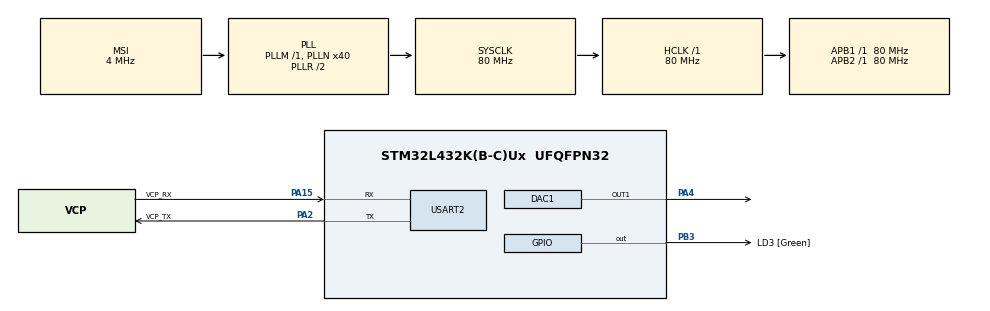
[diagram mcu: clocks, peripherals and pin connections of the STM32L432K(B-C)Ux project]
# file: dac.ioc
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DAC1.DAC_Trigger-DAC_OUT1=DAC_TRIGGER_T6_TRGO
Dma.DAC_CH1.0.Direction=DMA_MEMORY_TO_PERIPH
Dma.DAC_CH1.0.Instance=DMA1_Channel3
Dma.DAC_CH1.0.MemDataAlignment=DMA_MDATAALIGN_BYTE
Dma.DAC_CH1.0.MemInc=DMA_MINC_ENABLE
Dma.DAC_CH1.0.Mode=DMA_NORMAL
Dma.DAC_CH1.0.PeriphDataAlignment=DMA_PDATAALIGN_BYTE
Dma.DAC_CH1.0.PeriphInc=DMA_PINC_DISABLE
Dma.DAC_CH1.0.Priority=DMA_PRIORITY_LOW
Dma.Request0=DAC_CH1
Mcu.Family=STM32L4
Mcu.Name=STM32L432K(B-C)Ux
Mcu.Package=UFQFPN32
NVIC.DMA1_Channel3_IRQn=true\:0\:0\:false\:false\:true\:false
NVIC.PriorityGroup=NVIC_PRIORITYGROUP_4
PA0.GPIO_Label=MCO [High speed clock in]
PA0.Mode=HSE-External-Clock-Source-for-LittleOrca
PA0.Signal=RCC_CK_IN
PA13\ (JTMS-SWDIO).GPIO_Label=SWDIO
PA13\ (JTMS-SWDIO).Mode=Serial_Wire
PA13\ (JTMS-SWDIO).Signal=SYS_JTMS-SWDIO
PA14\ (JTCK-SWCLK).GPIO_Label=SWCLK
PA14\ (JTCK-SWCLK).Mode=Serial_Wire
PA14\ (JTCK-SWCLK).Signal=SYS_JTCK-SWCLK
PA15\ (JTDI).GPIO_Label=VCP_RX
PA15\ (JTDI).Mode=Asynchronous
PA15\ (JTDI).Signal=USART2_RX
PA2.GPIO_Label=VCP_TX
PA2.Mode=Asynchronous
PA2.Signal=USART2_TX
PA4.Signal=COMP_DAC11_group
PB3\ (JTDO-TRACESWO).GPIO_Label=LD3 [Green]
PB3\ (JTDO-TRACESWO).Signal=GPIO_Output
PC14-OSC32_IN\ (PC14).Mode=LSE-External-Oscillator
PC14-OSC32_IN\ (PC14).Signal=RCC_OSC32_IN
PC15-OSC32_OUT\ (PC15).Mode=LSE-External-Oscillator
PC15-OSC32_OUT\ (PC15).Signal=RCC_OSC32_OUT
ProjectManager.HeapSize=0x200
ProjectManager.StackSize=0x400
ProjectManager.TargetToolchain=TrueSTUDIO
RCC.AHBFreq_Value=80000000
RCC.APB1Freq_Value=80000000
RCC.APB1TimFreq_Value=80000000
RCC.APB2Freq_Value=80000000
RCC.APB2TimFreq_Value=80000000
RCC.CortexFreq_Value=80000000
RCC.HCLKFreq_Value=80000000
RCC.HSE_VALUE=8000000
RCC.HSI16_VALUE=16000000
RCC.HSI48_VALUE=48000000
RCC.HSI_VALUE=16000000
RCC.MSI_VALUE=4000000
RCC.PLLMUL=RCC_PLLMUL_4
RCC.PLLN=40
RCC.SYSCLKFreq_VALUE=80000000
RCC.SYSCLKSource=RCC_SYSCLKSOURCE_PLLCLK
RCC.VCOOutputFreq_Value=160000000
SH.COMP_DAC11_group.0=DAC1_OUT1,DAC_OUT1
TIM6.Period=1000
TIM6.Prescaler=10
TIM6.TIM_MasterOutputTrigger=TIM_TRGO_UPDATE
USART2.VirtualMode-Asynchronous=VM_ASYNC
VP_TIM6_VS_ClockSourceINT.Mode=Enable_Timer
board=NUCLEO-L432KC

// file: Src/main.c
/**
  ******************************************************************************
  * @file           : main.c
  * @brief          : Main program body
  ******************************************************************************
  ** This notice applies to any and all portions of this file
  * that are not between comment pairs USER CODE BEGIN and
  * USER CODE END. Other portions of this file, whether
  * inserted by the user or by software development tools
  * are owned by their respective copyright owners.
  *
  * COPYRIGHT(c) 2018 STMicroelectronics
  *
  * Redistribution and use in source and binary forms, with or without modification,
  * are permitted provided that the following conditions are met:
  *   1. Redistributions of source code must retain the above copyright notice,
  *      this list of conditions and the following disclaimer.
  *   2. Redistributions in binary form must reproduce the above copyright notice,
  *      this list of conditions and the following disclaimer in the documentation
  *      and/or other materials provided with the distribution.
  *   3. Neither the name of STMicroelectronics nor the names of its contributors
  *      may be used to endorse or promote products derived from this software
  *      without specific prior written permission.
  *
  * THIS SOFTWARE IS PROVIDED BY THE COPYRIGHT HOLDERS AND CONTRIBUTORS "AS IS"
  * AND ANY EXPRESS OR IMPLIED WARRANTIES, INCLUDING, BUT NOT LIMITED TO, THE
  * IMPLIED WARRANTIES OF MERCHANTABILITY AND FITNESS FOR A PARTICULAR PURPOSE ARE
  * DISCLAIMED. IN NO EVENT SHALL THE COPYRIGHT HOLDER OR CONTRIBUTORS BE LIABLE
  * FOR ANY DIRECT, INDIRECT, INCIDENTAL, SPECIAL, EXEMPLARY, OR CONSEQUENTIAL
  * DAMAGES (INCLUDING, BUT NOT LIMITED TO, PROCUREMENT OF SUBSTITUTE GOODS OR
  * SERVICES; LOSS OF USE, DATA, OR PROFITS; OR BUSINESS INTERRUPTION) HOWEVER
  * CAUSED AND ON ANY THEORY OF LIABILITY, WHETHER IN CONTRACT, STRICT LIABILITY,
  * OR TORT (INCLUDING NEGLIGENCE OR OTHERWISE) ARISING IN ANY WAY OUT OF THE USE
  * OF THIS SOFTWARE, EVEN IF ADVISED OF THE POSSIBILITY OF SUCH DAMAGE.
  *
  ******************************************************************************
  */
#include "main.h"
#include "stm32l4xx_hal.h"

/* USER CODE BEGIN Includes */

#include "sampleplayer.h"

/* USER CODE END Includes */

DAC_HandleTypeDef hdac1;
DMA_HandleTypeDef hdma_dac_ch1;

TIM_HandleTypeDef htim6;

UART_HandleTypeDef huart2;

/* USER CODE BEGIN PV */
/* Private variables ---------------------------------------------------------*/

/* USER CODE END PV */

void SystemClock_Config(void);
static void MX_GPIO_Init(void);
static void MX_DMA_Init(void);
static void MX_USART2_UART_Init(void);
static void MX_DAC1_Init(void);
static void MX_TIM6_Init(void);

/* USER CODE BEGIN PFP */
/* Private function prototypes -----------------------------------------------*/

/* USER CODE END PFP */

int main(void)
{

  /* MCU Configuration----------------------------------------------------------*/

  /* Reset of all peripherals, Initializes the Flash interface and the Systick. */
  HAL_Init();

  /* Configure the system clock */
  SystemClock_Config();

  /* Initialize all configured peripherals */
  MX_GPIO_Init();
  MX_DMA_Init();
  MX_USART2_UART_Init();
  MX_DAC1_Init();
  MX_TIM6_Init();
  /* USER CODE BEGIN 2 */

  sampleplayer_init();

  /* USER CODE END 2 */

  /* Infinite loop */
  while (1)
  {

  /* USER CODE BEGIN 3 */

    sampleplayer_play_click();
    HAL_Delay(500);

  }
  /* USER CODE END 3 */

}

void SystemClock_Config(void)
{

  RCC_OscInitTypeDef RCC_OscInitStruct;
  RCC_ClkInitTypeDef RCC_ClkInitStruct;
  RCC_PeriphCLKInitTypeDef PeriphClkInit;

    /**Configure LSE Drive Capability
    */
  __HAL_RCC_LSEDRIVE_CONFIG(RCC_LSEDRIVE_LOW);

    /**Initializes the CPU, AHB and APB busses clocks
    */
  RCC_OscInitStruct.OscillatorType = RCC_OSCILLATORTYPE_LSE|RCC_OSCILLATORTYPE_MSI;
  RCC_OscInitStruct.LSEState = RCC_LSE_ON;
  RCC_OscInitStruct.MSIState = RCC_MSI_ON;
  RCC_OscInitStruct.MSICalibrationValue = 0;
  RCC_OscInitStruct.MSIClockRange = RCC_MSIRANGE_6;
  RCC_OscInitStruct.PLL.PLLState = RCC_PLL_ON;
  RCC_OscInitStruct.PLL.PLLSource = RCC_PLLSOURCE_MSI;
  RCC_OscInitStruct.PLL.PLLM = 1;
  RCC_OscInitStruct.PLL.PLLN = 40;
  RCC_OscInitStruct.PLL.PLLP = RCC_PLLP_DIV7;
  RCC_OscInitStruct.PLL.PLLQ = RCC_PLLQ_DIV2;
  RCC_OscInitStruct.PLL.PLLR = RCC_PLLR_DIV2;
  if (HAL_RCC_OscConfig(&RCC_OscInitStruct) != HAL_OK)
  {
    _Error_Handler(__FILE__, __LINE__);
  }

    /**Initializes the CPU, AHB and APB busses clocks
    */
  RCC_ClkInitStruct.ClockType = RCC_CLOCKTYPE_HCLK|RCC_CLOCKTYPE_SYSCLK
                              |RCC_CLOCKTYPE_PCLK1|RCC_CLOCKTYPE_PCLK2;
  RCC_ClkInitStruct.SYSCLKSource = RCC_SYSCLKSOURCE_PLLCLK;
  RCC_ClkInitStruct.AHBCLKDivider = RCC_SYSCLK_DIV1;
  RCC_ClkInitStruct.APB1CLKDivider = RCC_HCLK_DIV1;
  RCC_ClkInitStruct.APB2CLKDivider = RCC_HCLK_DIV1;

  if (HAL_RCC_ClockConfig(&RCC_ClkInitStruct, FLASH_LATENCY_4) != HAL_OK)
  {
    _Error_Handler(__FILE__, __LINE__);
  }

  PeriphClkInit.PeriphClockSelection = RCC_PERIPHCLK_USART2;
  PeriphClkInit.Usart2ClockSelection = RCC_USART2CLKSOURCE_PCLK1;
  if (HAL_RCCEx_PeriphCLKConfig(&PeriphClkInit) != HAL_OK)
  {
    _Error_Handler(__FILE__, __LINE__);
  }

    /**Configure the main internal regulator output voltage
    */
  if (HAL_PWREx_ControlVoltageScaling(PWR_REGULATOR_VOLTAGE_SCALE1) != HAL_OK)
  {
    _Error_Handler(__FILE__, __LINE__);
  }

    /**Configure the Systick interrupt time
    */
  HAL_SYSTICK_Config(HAL_RCC_GetHCLKFreq()/1000);

    /**Configure the Systick
    */
  HAL_SYSTICK_CLKSourceConfig(SYSTICK_CLKSOURCE_HCLK);

    /**Enable MSI Auto calibration
    */
  HAL_RCCEx_EnableMSIPLLMode();

  /* SysTick_IRQn interrupt configuration */
  HAL_NVIC_SetPriority(SysTick_IRQn, 0, 0);
}

/* DAC1 init function */
static void MX_DAC1_Init(void)
{

  DAC_ChannelConfTypeDef sConfig;

    /**DAC Initialization
    */
  hdac1.Instance = DAC1;
  if (HAL_DAC_Init(&hdac1) != HAL_OK)
  {
    _Error_Handler(__FILE__, __LINE__);
  }

    /**DAC channel OUT1 config
    */
  sConfig.DAC_SampleAndHold = DAC_SAMPLEANDHOLD_DISABLE;
  sConfig.DAC_Trigger = DAC_TRIGGER_T6_TRGO;
  sConfig.DAC_OutputBuffer = DAC_OUTPUTBUFFER_ENABLE;
  sConfig.DAC_ConnectOnChipPeripheral = DAC_CHIPCONNECT_DISABLE;
  sConfig.DAC_UserTrimming = DAC_TRIMMING_FACTORY;
  if (HAL_DAC_ConfigChannel(&hdac1, &sConfig, DAC_CHANNEL_1) != HAL_OK)
  {
    _Error_Handler(__FILE__, __LINE__);
  }

}

/* TIM6 init function */
static void MX_TIM6_Init(void)
{

  TIM_MasterConfigTypeDef sMasterConfig;

  htim6.Instance = TIM6;
  htim6.Init.Prescaler = 10;
  htim6.Init.CounterMode = TIM_COUNTERMODE_UP;
  htim6.Init.Period = 1000;
  htim6.Init.AutoReloadPreload = TIM_AUTORELOAD_PRELOAD_DISABLE;
  if (HAL_TIM_Base_Init(&htim6) != HAL_OK)
  {
    _Error_Handler(__FILE__, __LINE__);
  }

  sMasterConfig.MasterOutputTrigger = TIM_TRGO_UPDATE;
  sMasterConfig.MasterSlaveMode = TIM_MASTERSLAVEMODE_DISABLE;
  if (HAL_TIMEx_MasterConfigSynchronization(&htim6, &sMasterConfig) != HAL_OK)
  {
    _Error_Handler(__FILE__, __LINE__);
  }

}

/* USART2 init function */
static void MX_USART2_UART_Init(void)
{

  huart2.Instance = USART2;
  huart2.Init.BaudRate = 115200;
  huart2.Init.WordLength = UART_WORDLENGTH_7B;
  huart2.Init.StopBits = UART_STOPBITS_1;
  huart2.Init.Parity = UART_PARITY_NONE;
  huart2.Init.Mode = UART_MODE_TX_RX;
  huart2.Init.HwFlowCtl = UART_HWCONTROL_NONE;
  huart2.Init.OverSampling = UART_OVERSAMPLING_16;
  huart2.Init.OneBitSampling = UART_ONE_BIT_SAMPLE_DISABLE;
  huart2.AdvancedInit.AdvFeatureInit = UART_ADVFEATURE_NO_INIT;
  if (HAL_UART_Init(&huart2) != HAL_OK)
  {
    _Error_Handler(__FILE__, __LINE__);
  }

}

static void MX_DMA_Init(void)
{
  /* DMA controller clock enable */
  __HAL_RCC_DMA1_CLK_ENABLE();

  /* DMA interrupt init */
  /* DMA1_Channel3_IRQn interrupt configuration */
  HAL_NVIC_SetPriority(DMA1_Channel3_IRQn, 0, 0);
  HAL_NVIC_EnableIRQ(DMA1_Channel3_IRQn);

}

/** Configure pins as
        * Analog
        * Input
        * Output
        * EVENT_OUT
        * EXTI
*/
static void MX_GPIO_Init(void)
{

  GPIO_InitTypeDef GPIO_InitStruct;

  /* GPIO Ports Clock Enable */
  __HAL_RCC_GPIOC_CLK_ENABLE();
  __HAL_RCC_GPIOA_CLK_ENABLE();
  __HAL_RCC_GPIOB_CLK_ENABLE();

  /*Configure GPIO pin Output Level */
  HAL_GPIO_WritePin(LD3_GPIO_Port, LD3_Pin, GPIO_PIN_RESET);

  /*Configure GPIO pin : LD3_Pin */
  GPIO_InitStruct.Pin = LD3_Pin;
  GPIO_InitStruct.Mode = GPIO_MODE_OUTPUT_PP;
  GPIO_InitStruct.Pull = GPIO_NOPULL;
  GPIO_InitStruct.Speed = GPIO_SPEED_FREQ_LOW;
  HAL_GPIO_Init(LD3_GPIO_Port, &GPIO_InitStruct);

}

void _Error_Handler(char *file, int line)
{
  while(1)
  {
  }
}

/************************ (C) COPYRIGHT STMicroelectronics *****END OF FILE****/
